# nrf52840 register map
Vendor: Nordic Semiconductor; Series: nrf52; File version: 1
CPU: CM4 r0p1, little endian, MPU, FPU, 3 interrupt priority bits
Registers are 32-bit, read-write, reset 0x0 unless marked. A register's access mark holds for its fields unless they carry their own. Offsets are from the block's base; [hi:lo] are bit positions; lines under a group give offsets from that group; 'fields as' and 'values as' point back to an identical list.

## TWIM0 — I2C compatible Two-Wire Master Interface with EasyDMA 0
Base 0x40003000; alternate view of SPI0
Same registers: TWIM1 0x40004000 (alternate view of SPI1)
0x00 TASKS_STARTRX wo — Start TWI receive sequence
  [0] TASKS_STARTRX
0x08 TASKS_STARTTX wo — Start TWI transmit sequence
  [0] TASKS_STARTTX
0x14 TASKS_STOP wo — Stop TWI transaction. Must be issued while the TWI master is not suspended.
  [0] TASKS_STOP
0x1C TASKS_SUSPEND wo — Suspend TWI transaction
  [0] TASKS_SUSPEND
0x20 TASKS_RESUME wo — Resume TWI transaction
  [0] TASKS_RESUME
0x104 EVENTS_STOPPED — TWI stopped
  [0] EVENTS_STOPPED
0x124 EVENTS_ERROR — TWI error
  [0] EVENTS_ERROR
0x148 EVENTS_SUSPENDED — Last byte has been sent out after the SUSPEND task has been issued, TWI traffic is now suspended.
  [0] EVENTS_SUSPENDED
0x14C EVENTS_RXSTARTED — Receive sequence started
  [0] EVENTS_RXSTARTED
0x150 EVENTS_TXSTARTED — Transmit sequence started
  [0] EVENTS_TXSTARTED
0x15C EVENTS_LASTRX — Byte boundary, starting to receive the last byte
  [0] EVENTS_LASTRX
0x160 EVENTS_LASTTX — Byte boundary, starting to transmit the last byte
  [0] EVENTS_LASTTX
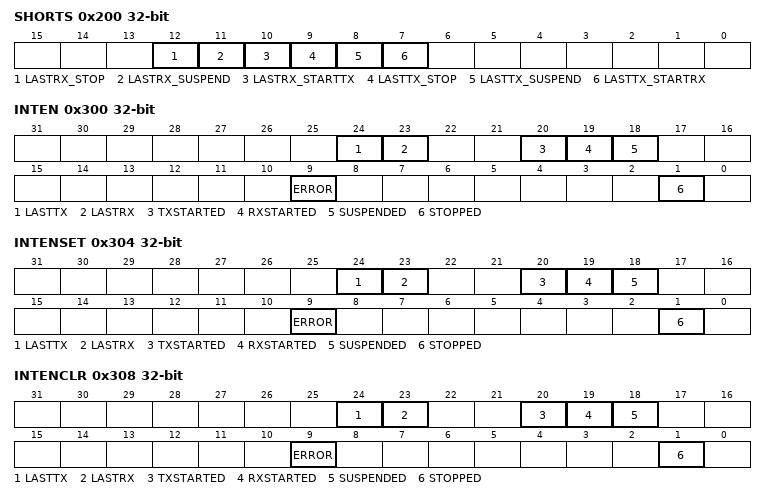
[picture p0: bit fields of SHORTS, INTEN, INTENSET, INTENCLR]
0x200 SHORTS — Shortcut register
  [all] fields
    0=Disabled (Disable shortcut); 1=Enabled (Enable shortcut)
  [12] LASTRX_STOP — Shortcut between LASTRX event and STOP task
  [11] LASTRX_SUSPEND — Shortcut between LASTRX event and SUSPEND task
  [10] LASTRX_STARTTX — Shortcut between LASTRX event and STARTTX task
  [9] LASTTX_STOP — Shortcut between LASTTX event and STOP task
  [8] LASTTX_SUSPEND — Shortcut between LASTTX event and SUSPEND task
  [7] LASTTX_STARTRX — Shortcut between LASTTX event and STARTRX task
0x300 INTEN — Enable or disable interrupt
  [all] fields
    0=Disabled; 1=Enabled
  [24] LASTTX — Enable or disable interrupt for LASTTX event
  [23] LASTRX — Enable or disable interrupt for LASTRX event
  [20] TXSTARTED — Enable or disable interrupt for TXSTARTED event
  [19] RXSTARTED — Enable or disable interrupt for RXSTARTED event
  [18] SUSPENDED — Enable or disable interrupt for SUSPENDED event
  [9] ERROR — Enable or disable interrupt for ERROR event
  [1] STOPPED — Enable or disable interrupt for STOPPED event
0x304 INTENSET — Enable interrupt
  [all] fields
    on read: 0=Disabled (Read: Disabled); 1=Enabled (Read: Enabled) | on write: 1=Set (Enable)
  [24] LASTTX — Write '1' to enable interrupt for LASTTX event
  [23] LASTRX — Write '1' to enable interrupt for LASTRX event
  [20] TXSTARTED — Write '1' to enable interrupt for TXSTARTED event
  [19] RXSTARTED — Write '1' to enable interrupt for RXSTARTED event
  [18] SUSPENDED — Write '1' to enable interrupt for SUSPENDED event
  [9] ERROR — Write '1' to enable interrupt for ERROR event
  [1] STOPPED — Write '1' to enable interrupt for STOPPED event
0x308 INTENCLR — Disable interrupt
  [all] fields
    on read: 0=Disabled (Read: Disabled); 1=Enabled (Read: Enabled) | on write: 1=Clear (Disable)
  [24] LASTTX — Write '1' to disable interrupt for LASTTX event
  [23] LASTRX — Write '1' to disable interrupt for LASTRX event
  [20] TXSTARTED — Write '1' to disable interrupt for TXSTARTED event
  [19] RXSTARTED — Write '1' to disable interrupt for RXSTARTED event
  [18] SUSPENDED — Write '1' to disable interrupt for SUSPENDED event
  [9] ERROR — Write '1' to disable interrupt for ERROR event
  [1] STOPPED — Write '1' to disable interrupt for STOPPED event
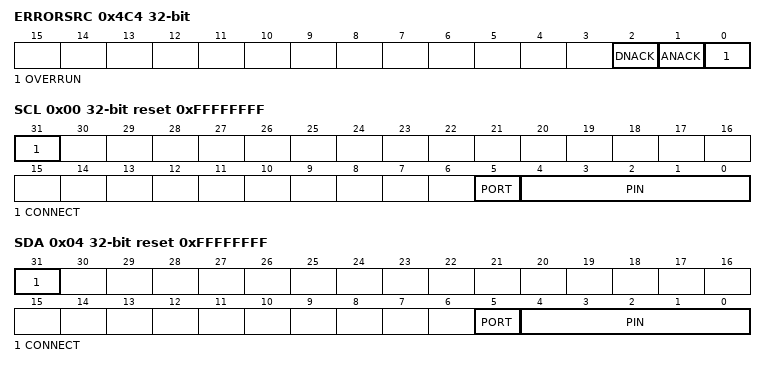
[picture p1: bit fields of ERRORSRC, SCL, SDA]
0x4C4 ERRORSRC write-1-clears — Error source
  [all] fields
    0=NotReceived (Error did not occur); 1=Received (Error occurred)
  [2] DNACK — NACK received after sending a data byte (write '1' to clear)
  [1] ANACK — NACK received after sending the address (write '1' to clear)
  [0] OVERRUN — Overrun error
0x500 ENABLE — Enable TWIM
  [3:0] ENABLE — Enable or disable TWIM
    0=Disabled (Disable TWIM); 6=Enabled (Enable TWIM)
0x508 PSEL group — Unspecified
  0x00 SCL reset 0xFFFFFFFF — Pin select for SCL signal
    [31] CONNECT — Connection
      1=Disconnected; 0=Connected
    [5] PORT — Port number
    [4:0] PIN — Pin number
  0x04 SDA reset 0xFFFFFFFF — Pin select for SDA signal
    fields as PSEL.SCL
0x524 FREQUENCY reset 0x4000000 — TWI frequency. Accuracy depends on the HFCLK source selected.
  [31:0] FREQUENCY — TWI master clock frequency
    0x1980000=K100 (100 kbps); 0x4000000=K250 (250 kbps); 0x6400000=K400 (400 kbps)
0x534 RXD group — RXD EasyDMA channel
  0x00 PTR — Data pointer
  0x04 MAXCNT — Maximum number of bytes in receive buffer
    [15:0] MAXCNT
  0x08 AMOUNT ro — Number of bytes transferred in the last transaction
    [15:0] AMOUNT — Number of bytes transferred in the last transaction. In case of NACK error, includes the NACK'ed byte.
  0x0C LIST — EasyDMA list type
    [2:0] LIST — List type
      0=Disabled (Disable EasyDMA list); 1=ArrayList (Use array list)
0x544 TXD group — TXD EasyDMA channel
  0x00 PTR — Data pointer
  0x04 MAXCNT — Maximum number of bytes in transmit buffer
    [15:0] MAXCNT
  0x08 AMOUNT ro — Number of bytes transferred in the last transaction
    fields as RXD.AMOUNT
  0x0C LIST — EasyDMA list type
    fields as RXD.LIST
0x588 ADDRESS — Address used in the TWI transfer
  [6:0] ADDRESS
